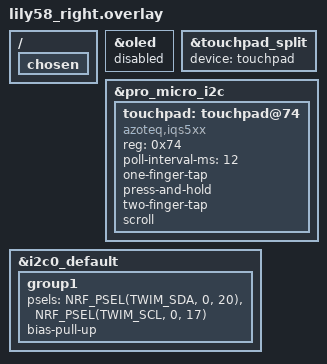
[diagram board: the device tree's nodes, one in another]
#include "touchpad.dtsi"

/ {
    chosen {
        /delete-property/ zephyr,display;
    };
};

/* The nice!view is removed from this half, and the stock lily58 OLED node would sit on the touchpad's I2C bus. */
&oled {
    status = "disabled";
};

&touchpad_split {
    device = <&touchpad>;
};

&pro_micro_i2c {
    status = "okay";

    touchpad: touchpad@74 {
        compatible = "azoteq,iqs5xx";
        reg = <0x74>;

        /* No rdy-gpios or reset-gpios on this adapter, so the driver polls. */
        poll-interval-ms = <12>;

        one-finger-tap;
        press-and-hold;
        two-finger-tap;
        scroll;
    };
};

/*
 * DEBUG: the adapter may not have I2C pull-ups, so enable the nRF's internal ones on SDA/SCL.
 * DEBUG: SDA and SCL are swapped (SDA on P0.20, SCL on P0.17) to test whether the cable crosses them.
 */
&i2c0_default {
    group1 {
        psels = <NRF_PSEL(TWIM_SDA, 0, 20)>, <NRF_PSEL(TWIM_SCL, 0, 17)>;
        bias-pull-up;
    };
};
